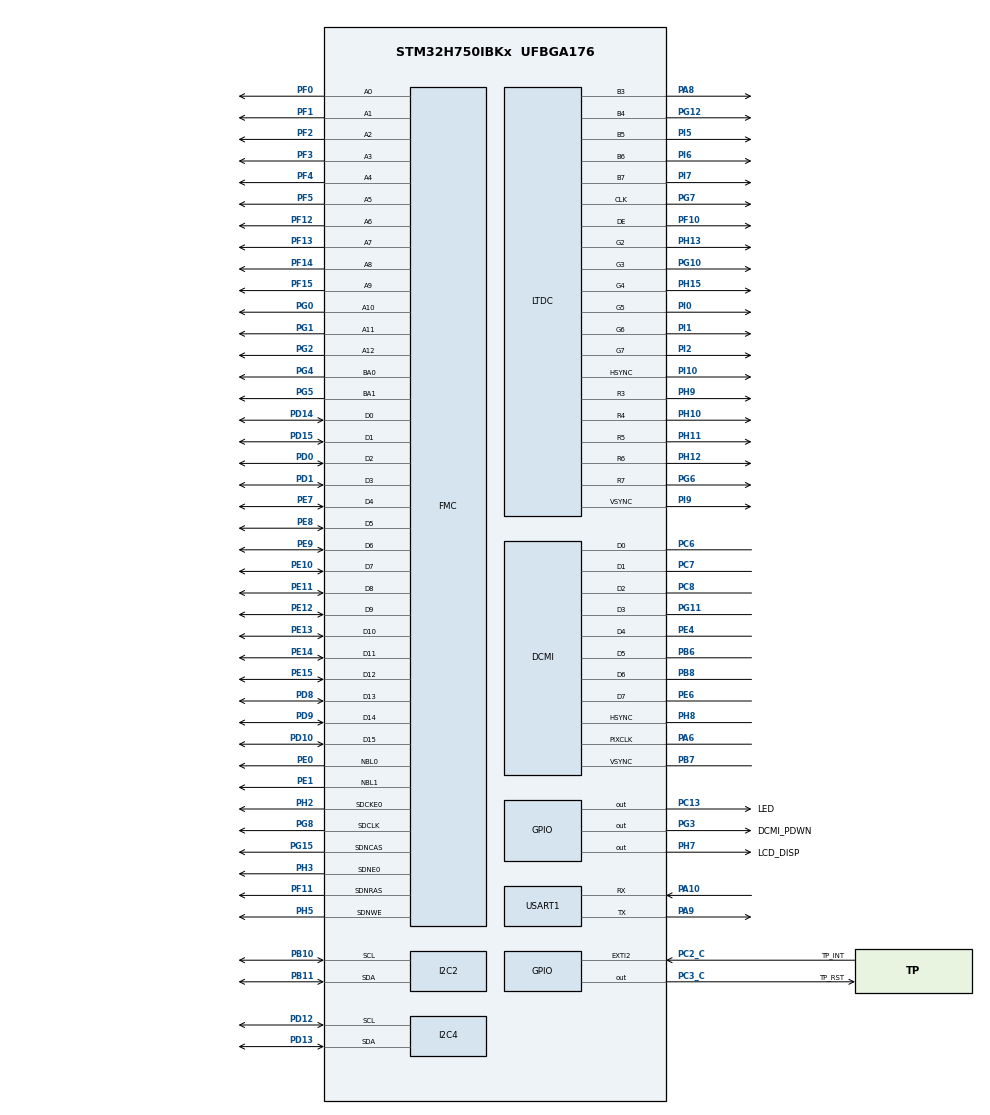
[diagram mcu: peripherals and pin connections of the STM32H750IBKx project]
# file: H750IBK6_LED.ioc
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CORTEX_M7.AccessPermission_Spec=MPU_REGION_FULL_ACCESS
CORTEX_M7.CPU_DCache=Enabled
CORTEX_M7.CPU_ICache=Enabled
CORTEX_M7.default_mode_Activation=1
DCMI.JPEGMode=DCMI_JPEG_DISABLE
DCMI.PCKPolarity=DCMI_PCKPOLARITY_RISING
DMA2D.ColorMode=DMA2D_OUTPUT_RGB565
Dma.DCMI.0.Direction=DMA_PERIPH_TO_MEMORY
Dma.DCMI.0.EventEnable=DISABLE
Dma.DCMI.0.FIFOMode=DMA_FIFOMODE_ENABLE
Dma.DCMI.0.FIFOThreshold=DMA_FIFO_THRESHOLD_FULL
Dma.DCMI.0.Instance=DMA1_Stream0
Dma.DCMI.0.MemBurst=DMA_MBURST_INC8
Dma.DCMI.0.MemDataAlignment=DMA_MDATAALIGN_HALFWORD
Dma.DCMI.0.MemInc=DMA_MINC_ENABLE
Dma.DCMI.0.Mode=DMA_CIRCULAR
Dma.DCMI.0.PeriphBurst=DMA_PBURST_SINGLE
Dma.DCMI.0.PeriphDataAlignment=DMA_PDATAALIGN_WORD
Dma.DCMI.0.PeriphInc=DMA_PINC_DISABLE
Dma.DCMI.0.Polarity=HAL_DMAMUX_REQ_GEN_RISING
Dma.DCMI.0.Priority=DMA_PRIORITY_VERY_HIGH
Dma.DCMI.0.RequestNumber=1
Dma.DCMI.0.SignalID=NONE
Dma.DCMI.0.SyncEnable=DISABLE
Dma.DCMI.0.SyncPolarity=HAL_DMAMUX_SYNC_NO_EVENT
Dma.DCMI.0.SyncRequestNumber=1
Dma.DCMI.0.SyncSignalID=NONE
Dma.Request0=DCMI
FMC.CASLatency1=FMC_SDRAM_CAS_LATENCY_3
FMC.ColumnBitsNumber1=FMC_SDRAM_COLUMN_BITS_NUM_9
FMC.ExitSelfRefreshDelay1=7
FMC.LoadToActiveDelay1=2
FMC.RCDDelay1=2
FMC.RPDelay1=2
FMC.RPDelay2=2
FMC.ReadPipeDelay1=FMC_SDRAM_RPIPE_DELAY_1
FMC.ReadPipeDelay2=FMC_SDRAM_RPIPE_DELAY_1
FMC.RowCycleDelay1=7
FMC.RowCycleDelay2=7
FMC.SDClockPeriod1=FMC_SDRAM_CLOCK_PERIOD_2
FMC.SDClockPeriod2=FMC_SDRAM_CLOCK_PERIOD_2
FMC.SelfRefreshTime1=4
FMC.WriteRecoveryTime1=3
I2C2.Timing=0x307075B1
I2C4.Timing=0x307075B1
LTDC.ActiveW=800
LTDC.Alpha_L0=255
LTDC.FBStartAdress_L0=0xc0000000
LTDC.HBP=46
LTDC.HFP=40
LTDC.HSync=1
LTDC.ImageHeight_L0=480
LTDC.ImageWidth_L0=800
LTDC.Layers=0
LTDC.PixelFormat_L0=LTDC_PIXEL_FORMAT_RGB565
LTDC.VBP=23
LTDC.VFP=10
LTDC.VSync=3
LTDC.WindowX1_L0=800
LTDC.WindowY1_L0=480
Mcu.Family=STM32H7
Mcu.Name=STM32H750IBKx
Mcu.Package=UFBGA176
NVIC.DCMI_IRQn=true\:0\:0\:false\:false\:true\:true\:true\:true
NVIC.DMA1_Stream0_IRQn=true\:0\:0\:false\:false\:true\:false\:true\:true
NVIC.DMA2D_IRQn=true\:0\:0\:false\:false\:true\:true\:true\:true
NVIC.FMC_IRQn=true\:0\:0\:false\:false\:true\:true\:true\:true
NVIC.LTDC_IRQn=true\:0\:0\:false\:false\:true\:true\:true\:true
NVIC.PriorityGroup=NVIC_PRIORITYGROUP_4
NVIC.TIM7_IRQn=true\:15\:0\:false\:false\:true\:false\:true\:true
NVIC.TimeBase=TIM7_IRQn
NVIC.TimeBaseIP=TIM7
PA10.Mode=Asynchronous
PA10.Signal=USART1_RX
PA13\ (JTMS/SWDIO).Mode=Serial_Wire
PA13\ (JTMS/SWDIO).Signal=DEBUG_JTMS-SWDIO
PA14\ (JTCK/SWCLK).Mode=Serial_Wire
PA14\ (JTCK/SWCLK).Signal=DEBUG_JTCK-SWCLK
PA6.Mode=Slave_8_bits_External_Synchro
PA6.Signal=DCMI_PIXCLK
PA8.Mode=RGB565
PA8.Signal=LTDC_B3
PA9.Mode=Asynchronous
PA9.Signal=USART1_TX
PB10.GPIO_Pu=GPIO_PULLUP
PB10.Mode=I2C
PB10.Signal=I2C2_SCL
PB11.GPIO_Pu=GPIO_PULLUP
PB11.Mode=I2C
PB11.Signal=I2C2_SDA
PB6.Mode=Slave_8_bits_External_Synchro
PB6.Signal=DCMI_D5
PB7.Mode=Slave_8_bits_External_Synchro
PB7.Signal=DCMI_VSYNC
PB8.Mode=Slave_8_bits_External_Synchro
PB8.Signal=DCMI_D6
PC13.GPIO_Label=LED
PC13.PinState=GPIO_PIN_SET
PC13.Signal=GPIO_Output
PC14-OSC32_IN\ (OSC32_IN).Mode=LSE-External-Oscillator
PC14-OSC32_IN\ (OSC32_IN).Signal=RCC_OSC32_IN
PC15-OSC32_OUT\ (OSC32_OUT).Mode=LSE-External-Oscillator
PC15-OSC32_OUT\ (OSC32_OUT).Signal=RCC_OSC32_OUT
PC2_C.GPIO_Label=TP_INT
PC2_C.GPIO_ModeDefaultEXTI=GPIO_MODE_IT_FALLING
PC2_C.GPIO_PuPd=GPIO_PULLUP
PC2_C.Signal=GPXTI2
PC3_C.GPIO_Label=TP_RST
PC3_C.GPIO_ModeDefaultOutputPP=GPIO_MODE_OUTPUT_PP
PC3_C.GPIO_PuPd=GPIO_PULLUP
PC3_C.GPIO_Speed=GPIO_SPEED_FREQ_MEDIUM
PC3_C.PinState=GPIO_PIN_SET
PC3_C.Signal=GPIO_Output
PC6.Mode=Slave_8_bits_External_Synchro
PC6.Signal=DCMI_D0
PC7.Mode=Slave_8_bits_External_Synchro
PC7.Signal=DCMI_D1
PC8.Mode=Slave_8_bits_External_Synchro
PC8.Signal=DCMI_D2
PD0.Signal=FMC_D2_DA2
PD1.Signal=FMC_D3_DA3
PD10.Signal=FMC_D15_DA15
PD12.GPIO_Pu=GPIO_PULLUP
PD12.GPIO_Speed=GPIO_SPEED_FREQ_LOW
PD12.Mode=I2C
PD12.Signal=I2C4_SCL
PD13.GPIO_Pu=GPIO_PULLUP
PD13.GPIO_Speed=GPIO_SPEED_FREQ_LOW
PD13.Mode=I2C
PD13.Signal=I2C4_SDA
PD14.Signal=FMC_D0_DA0
PD15.Signal=FMC_D1_DA1
PD8.Signal=FMC_D13_DA13
PD9.Signal=FMC_D14_DA14
PE0.Signal=FMC_NBL0
PE1.Signal=FMC_NBL1
PE10.Signal=FMC_D7_DA7
PE11.Signal=FMC_D8_DA8
PE12.Signal=FMC_D9_DA9
PE13.Signal=FMC_D10_DA10
PE14.Signal=FMC_D11_DA11
PE15.Signal=FMC_D12_DA12
PE4.Mode=Slave_8_bits_External_Synchro
PE4.Signal=DCMI_D4
PE6.Mode=Slave_8_bits_External_Synchro
PE6.Signal=DCMI_D7
PE7.Signal=FMC_D4_DA4
PE8.Signal=FMC_D5_DA5
PE9.Signal=FMC_D6_DA6
PF0.Signal=FMC_A0
PF1.Signal=FMC_A1
PF10.Mode=RGB565
PF10.Signal=LTDC_DE
PF11.Signal=FMC_SDNRAS
PF12.Signal=FMC_A6
PF13.Signal=FMC_A7
PF14.Signal=FMC_A8
PF15.Signal=FMC_A9
PF2.Signal=FMC_A2
PF3.Signal=FMC_A3
PF4.Signal=FMC_A4
PF5.Signal=FMC_A5
PG0.Signal=FMC_A10
PG1.Signal=FMC_A11
PG10.Mode=RGB565
PG10.Signal=LTDC_G3
PG11.Mode=Slave_8_bits_External_Synchro
PG11.Signal=DCMI_D3
PG12.Mode=RGB565
PG12.Signal=LTDC_B4
PG15.Signal=FMC_SDNCAS
PG2.Signal=FMC_A12
PG3.GPIO_Label=DCMI_PDWN
PG3.GPIO_PuPd=GPIO_PULLDOWN
PG3.PinState=GPIO_PIN_RESET
PG3.Signal=GPIO_Output
PG4.Signal=FMC_A14_BA0
PG5.Signal=FMC_A15_BA1
PG6.Mode=RGB565
PG6.Signal=LTDC_R7
PG7.Mode=RGB565
PG7.Signal=LTDC_CLK
PG8.Signal=FMC_SDCLK
PH0-OSC_IN\ (PH0).Mode=HSE-External-Oscillator
PH0-OSC_IN\ (PH0).Signal=RCC_OSC_IN
PH1-OSC_OUT\ (PH1).Mode=HSE-External-Oscillator
PH1-OSC_OUT\ (PH1).Signal=RCC_OSC_OUT
PH10.Mode=RGB565
PH10.Signal=LTDC_R4
PH11.Mode=RGB565
PH11.Signal=LTDC_R5
PH12.Mode=RGB565
PH12.Signal=LTDC_R6
PH13.Mode=RGB565
PH13.Signal=LTDC_G2
PH15.Mode=RGB565
PH15.Signal=LTDC_G4
PH2.Mode=SdramChipSelect1_1
PH2.Signal=FMC_SDCKE0
PH3.Mode=SdramChipSelect1_1
PH3.Signal=FMC_SDNE0
PH5.Signal=FMC_SDNWE
PH7.GPIO_Label=LCD_DISP
PH7.GPIO_PuPd=GPIO_PULLUP
PH7.PinState=GPIO_PIN_SET
PH7.Signal=GPIO_Output
PH8.Mode=Slave_8_bits_External_Synchro
PH8.Signal=DCMI_HSYNC
PH9.Mode=RGB565
PH9.Signal=LTDC_R3
PI0.Mode=RGB565
PI0.Signal=LTDC_G5
PI1.Mode=RGB565
PI1.Signal=LTDC_G6
PI10.Mode=RGB565
PI10.Signal=LTDC_HSYNC
PI2.Mode=RGB565
PI2.Signal=LTDC_G7
PI5.Mode=RGB565
PI5.Signal=LTDC_B5
PI6.Mode=RGB565
PI6.Signal=LTDC_B6
PI7.Mode=RGB565
PI7.Signal=LTDC_B7
PI9.Mode=RGB565
PI9.Signal=LTDC_VSYNC
ProjectManager.HeapSize=0x800
ProjectManager.StackSize=0x800
ProjectManager.TargetToolchain=MDK-ARM V5.32
RCC.ADCFreq_Value=50390625
RCC.APB1Freq_Value=120000000
RCC.APB2Freq_Value=120000000
RCC.APB3Freq_Value=120000000
RCC.APB4Freq_Value=120000000
RCC.CortexFreq_Value=480000000
RCC.D1PPRE=RCC_APB3_DIV2
RCC.D2PPRE1=RCC_APB1_DIV2
RCC.D2PPRE2=RCC_APB2_DIV2
RCC.D3PPRE=RCC_APB4_DIV2
RCC.DIVM1=5
RCC.DIVM3=25
RCC.DIVN1=192
RCC.DIVN3=150
RCC.DIVQ1=80
RCC.DIVR3=6
RCC.HCLKFreq_Value=240000000
RCC.HPRE=RCC_HCLK_DIV2
RCC.LSE_Timout=500
RCC.PLLSourceVirtual=RCC_PLLSOURCE_HSE
RCC.ProductRev=revV
RCC.SYSCLKFreq_VALUE=480000000
RCC.SYSCLKSource=RCC_SYSCLKSOURCE_PLLCLK
RCC.SupplySource=PWR_LDO_SUPPLY
RCC.USBFreq_Value=12000000
SH.FMC_A0.0=FMC_A0,13b-sda1
SH.FMC_A1.0=FMC_A1,13b-sda1
SH.FMC_A10.0=FMC_A10,13b-sda1
SH.FMC_A11.0=FMC_A11,13b-sda1
SH.FMC_A12.0=FMC_A12,13b-sda1
SH.FMC_A14_BA0.0=FMC_BA0,FourSdramBanks1
SH.FMC_A15_BA1.0=FMC_BA1,FourSdramBanks1
SH.FMC_A2.0=FMC_A2,13b-sda1
SH.FMC_A3.0=FMC_A3,13b-sda1
SH.FMC_A4.0=FMC_A4,13b-sda1
SH.FMC_A5.0=FMC_A5,13b-sda1
SH.FMC_A6.0=FMC_A6,13b-sda1
SH.FMC_A7.0=FMC_A7,13b-sda1
SH.FMC_A8.0=FMC_A8,13b-sda1
SH.FMC_A9.0=FMC_A9,13b-sda1
SH.FMC_D0_DA0.0=FMC_D0,sd-16b-d1
SH.FMC_D10_DA10.0=FMC_D10,sd-16b-d1
SH.FMC_D11_DA11.0=FMC_D11,sd-16b-d1
SH.FMC_D12_DA12.0=FMC_D12,sd-16b-d1
SH.FMC_D13_DA13.0=FMC_D13,sd-16b-d1
SH.FMC_D14_DA14.0=FMC_D14,sd-16b-d1
SH.FMC_D15_DA15.0=FMC_D15,sd-16b-d1
SH.FMC_D1_DA1.0=FMC_D1,sd-16b-d1
SH.FMC_D2_DA2.0=FMC_D2,sd-16b-d1
SH.FMC_D3_DA3.0=FMC_D3,sd-16b-d1
SH.FMC_D4_DA4.0=FMC_D4,sd-16b-d1
SH.FMC_D5_DA5.0=FMC_D5,sd-16b-d1
SH.FMC_D6_DA6.0=FMC_D6,sd-16b-d1
SH.FMC_D7_DA7.0=FMC_D7,sd-16b-d1
SH.FMC_D8_DA8.0=FMC_D8,sd-16b-d1
SH.FMC_D9_DA9.0=FMC_D9,sd-16b-d1
SH.FMC_NBL0.0=FMC_NBL0,Sd2ByteEnable1
SH.FMC_NBL1.0=FMC_NBL1,Sd2ByteEnable1
SH.FMC_SDCLK.0=FMC_SDCLK,13b-sda1
SH.FMC_SDNCAS.0=FMC_SDNCAS,13b-sda1
SH.FMC_SDNRAS.0=FMC_SDNRAS,13b-sda1
SH.FMC_SDNWE.0=FMC_SDNWE,13b-sda1
STMicroelectronics.X-CUBE-TOUCHGFX.4.21.0.tgfx_address1=0xc0000000
STMicroelectronics.X-CUBE-TOUCHGFX.4.21.0.tgfx_address2=0xc00bb800
STMicroelectronics.X-CUBE-TOUCHGFX.4.21.0.tgfx_buffering_strategy=Double
STMicroelectronics.X-CUBE-TOUCHGFX.4.21.0.tgfx_display_interface=disp_ltdc
STMicroelectronics.X-CUBE-TOUCHGFX.4.21.0.tgfx_hardware_accelerator=dma_2d
STMicroelectronics.X-CUBE-TOUCHGFX.4.21.0.tgfx_location=By Address
STMicroelectronics.X-CUBE-TOUCHGFX.4.21.0.tgfx_oswrapper=CMSIS V2
STMicroelectronics.X-CUBE-TOUCHGFX.4.21.0.tgfx_vector_rendering=Enabled
STMicroelectronics.X-CUBE-TOUCHGFX.4.21.0.tgfx_vsync=vsync_ltdc
STMicroelectronics.X-CUBE-TOUCHGFX.4.21.0_IsPackSelfContextualization=true
USART1.VirtualMode-Asynchronous=VM_ASYNC
VP_DMA2D_VS_DMA2D.Mode=DMA2D_Activate
VP_SYS_VS_tim7.Mode=TIM7
board=custom

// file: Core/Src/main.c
/* USER CODE BEGIN Header */
/**
  ******************************************************************************
  * @file           : main.c
  * @brief          : Main program body
  ******************************************************************************
  * @attention
  *
  * Copyright (c) 2023 STMicroelectronics.
  * All rights reserved.
  *
  * This software is licensed under terms that can be found in the LICENSE file
  * in the root directory of this software component.
  * If no LICENSE file comes with this software, it is provided AS-IS.
  *
  ******************************************************************************
  */
/* USER CODE END Header */
#include "main.h"
#include "dcmi.h"
#include "dma.h"
#include "dma2d.h"
#include "i2c.h"
#include "ltdc.h"
#include "usart.h"
#include "gpio.h"
#include "fmc.h"

/* USER CODE BEGIN Includes */
#include "bsp_sdram.h"
#include "gt911.h"
#include "bsp_ov2640.h"
/* USER CODE END Includes */

void SystemClock_Config(void);
static void MPU_Config(void);

/* USER CODE BEGIN 0 */
#ifdef __GNUC__
#define PUTCHAR_PROTOTYPE int __io_putchar(int ch)
#else
#define PUTCHAR_PROTOTYPE int fputc(int ch, FILE *f)
#endif
PUTCHAR_PROTOTYPE
{
    HAL_UART_Transmit(&huart1 , (uint8_t *)&ch, 1, 0xFFFF);
    return ch;
}

TS_StateTypeDef state;
OV2640_IDTypeDef OV2640_Camera_ID;
/* USER CODE END 0 */

int main(void)
{
  /* USER CODE BEGIN 1 */
	SCB_EnableICache();
  /* USER CODE END 1 */

  /* MPU Configuration--------------------------------------------------------*/
  MPU_Config();

  /* Enable I-Cache---------------------------------------------------------*/
  SCB_EnableICache();

  /* Enable D-Cache---------------------------------------------------------*/
  SCB_EnableDCache();

  /* MCU Configuration--------------------------------------------------------*/

  /* Reset of all peripherals, Initializes the Flash interface and the Systick. */
  HAL_Init();

  /* Configure the system clock */
  SystemClock_Config();

  /* Initialize all configured peripherals */
  MX_GPIO_Init();
  MX_DMA_Init();
  MX_USART1_UART_Init();
  MX_DMA2D_Init();
  MX_LTDC_Init();
  MX_I2C4_Init();
  MX_DCMI_Init();
  MX_FMC_Init();
  MX_I2C2_Init();
  /* USER CODE BEGIN 2 */
	SDRAM_InitSequence();
	gt911_init();
	OV2640_ReadID(&OV2640_Camera_ID);
	printf("OV2640_Camera_ID:0x%x\t0x%0x\r\n",OV2640_Camera_ID.Manufacturer_ID1,OV2640_Camera_ID.Manufacturer_ID2);
	if(OV2640_Camera_ID.PIDH  == 0x26)
		printf("PIDH:0x%x\tPIDL:0x%x\r\n",OV2640_Camera_ID.PIDH ,OV2640_Camera_ID.PIDL);
	else
	{
		printf("没有检测到OV2640摄像头，请重新检查连接。");
		while(1);
	}
	OV2640_UXGAConfig();
	OV2640_Init();
  /* USER CODE END 2 */

  /* Infinite loop */
  /* USER CODE BEGIN WHILE */
  while (1)
  {
		HAL_GPIO_TogglePin(LED_GPIO_Port,LED_Pin);
		HAL_Delay(100);
    /* USER CODE END WHILE */

  }
}

void SystemClock_Config(void)
{
  RCC_OscInitTypeDef RCC_OscInitStruct = {0};
  RCC_ClkInitTypeDef RCC_ClkInitStruct = {0};

  /** Supply configuration update enable
  */
  HAL_PWREx_ConfigSupply(PWR_LDO_SUPPLY);

  /** Configure the main internal regulator output voltage
  */
  __HAL_PWR_VOLTAGESCALING_CONFIG(PWR_REGULATOR_VOLTAGE_SCALE1);

  while(!__HAL_PWR_GET_FLAG(PWR_FLAG_VOSRDY)) {}

  __HAL_RCC_SYSCFG_CLK_ENABLE();
  __HAL_PWR_VOLTAGESCALING_CONFIG(PWR_REGULATOR_VOLTAGE_SCALE0);

  while(!__HAL_PWR_GET_FLAG(PWR_FLAG_VOSRDY)) {}

  /** Macro to configure the PLL clock source
  */
  __HAL_RCC_PLL_PLLSOURCE_CONFIG(RCC_PLLSOURCE_HSE);

  /** Initializes the RCC Oscillators according to the specified parameters
  * in the RCC_OscInitTypeDef structure.
  */
  RCC_OscInitStruct.OscillatorType = RCC_OSCILLATORTYPE_HSE;
  RCC_OscInitStruct.HSEState = RCC_HSE_ON;
  RCC_OscInitStruct.PLL.PLLState = RCC_PLL_ON;
  RCC_OscInitStruct.PLL.PLLSource = RCC_PLLSOURCE_HSE;
  RCC_OscInitStruct.PLL.PLLM = 5;
  RCC_OscInitStruct.PLL.PLLN = 192;
  RCC_OscInitStruct.PLL.PLLP = 2;
  RCC_OscInitStruct.PLL.PLLQ = 80;
  RCC_OscInitStruct.PLL.PLLR = 2;
  RCC_OscInitStruct.PLL.PLLRGE = RCC_PLL1VCIRANGE_2;
  RCC_OscInitStruct.PLL.PLLVCOSEL = RCC_PLL1VCOWIDE;
  RCC_OscInitStruct.PLL.PLLFRACN = 0;
  if (HAL_RCC_OscConfig(&RCC_OscInitStruct) != HAL_OK)
  {
    Error_Handler();
  }

  /** Initializes the CPU, AHB and APB buses clocks
  */
  RCC_ClkInitStruct.ClockType = RCC_CLOCKTYPE_HCLK|RCC_CLOCKTYPE_SYSCLK
                              |RCC_CLOCKTYPE_PCLK1|RCC_CLOCKTYPE_PCLK2
                              |RCC_CLOCKTYPE_D3PCLK1|RCC_CLOCKTYPE_D1PCLK1;
  RCC_ClkInitStruct.SYSCLKSource = RCC_SYSCLKSOURCE_PLLCLK;
  RCC_ClkInitStruct.SYSCLKDivider = RCC_SYSCLK_DIV1;
  RCC_ClkInitStruct.AHBCLKDivider = RCC_HCLK_DIV2;
  RCC_ClkInitStruct.APB3CLKDivider = RCC_APB3_DIV2;
  RCC_ClkInitStruct.APB1CLKDivider = RCC_APB1_DIV2;
  RCC_ClkInitStruct.APB2CLKDivider = RCC_APB2_DIV2;
  RCC_ClkInitStruct.APB4CLKDivider = RCC_APB4_DIV2;

  if (HAL_RCC_ClockConfig(&RCC_ClkInitStruct, FLASH_LATENCY_4) != HAL_OK)
  {
    Error_Handler();
  }
}

/* MPU Configuration */

void MPU_Config(void)
{
  MPU_Region_InitTypeDef MPU_InitStruct = {0};

  /* Disables the MPU */
  HAL_MPU_Disable();

  /** Initializes and configures the Region and the memory to be protected
  */
  MPU_InitStruct.Enable = MPU_REGION_ENABLE;
  MPU_InitStruct.Number = MPU_REGION_NUMBER0;
  MPU_InitStruct.BaseAddress = 0x0;
  MPU_InitStruct.Size = MPU_REGION_SIZE_4GB;
  MPU_InitStruct.SubRegionDisable = 0x87;
  MPU_InitStruct.TypeExtField = MPU_TEX_LEVEL0;
  MPU_InitStruct.AccessPermission = MPU_REGION_FULL_ACCESS;
  MPU_InitStruct.DisableExec = MPU_INSTRUCTION_ACCESS_DISABLE;
  MPU_InitStruct.IsShareable = MPU_ACCESS_SHAREABLE;
  MPU_InitStruct.IsCacheable = MPU_ACCESS_NOT_CACHEABLE;
  MPU_InitStruct.IsBufferable = MPU_ACCESS_NOT_BUFFERABLE;

  HAL_MPU_ConfigRegion(&MPU_InitStruct);
  /* Enables the MPU */
  HAL_MPU_Enable(MPU_PRIVILEGED_DEFAULT);

}

void HAL_TIM_PeriodElapsedCallback(TIM_HandleTypeDef *htim)
{
  if (htim->Instance == TIM7) {
    HAL_IncTick();
  }
}

void Error_Handler(void)
{
  __disable_irq();
  while (1)
  {
  }
}
